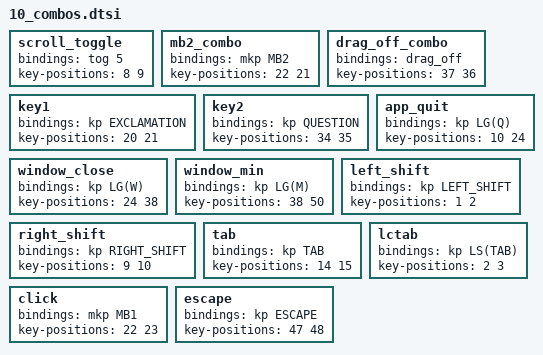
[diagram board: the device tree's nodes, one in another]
/* ============================================================
 * 10_combos.dtsi — コンボ定義
 *
 * combos { compatible = "zmk,combos"; } の内側でインクルードされる。
 * ============================================================ */

scroll_toggle {
    bindings = <&tog 5>;
    key-positions = <8 9>;
};

mb2_combo {
    bindings = <&mkp MB2>;
    key-positions = <22 21>;
};

drag_off_combo {
    bindings = <&drag_off>;
    key-positions = <37 36>;
};

key1 {
    bindings = <&kp EXCLAMATION>;
    key-positions = <20 21>;
};

key2 {
    bindings = <&kp QUESTION>;
    key-positions = <34 35>;
};

app_quit {
    bindings = <&kp LG(Q)>;
    key-positions = <10 24>;
};

window_close {
    bindings = <&kp LG(W)>;
    key-positions = <24 38>;
};

window_min {
    bindings = <&kp LG(M)>;
    key-positions = <38 50>;
};

left_shift {
    bindings = <&kp LEFT_SHIFT>;
    key-positions = <1 2>;
};

right_shift {
    bindings = <&kp RIGHT_SHIFT>;
    key-positions = <9 10>;
};

tab {
    bindings = <&kp TAB>;
    key-positions = <14 15>;
};

lctab {
    bindings = <&kp LS(TAB)>;
    key-positions = <2 3>;
};

click {
    bindings = <&mkp MB1>;
    key-positions = <22 23>;
};

escape {
    bindings = <&kp ESCAPE>;
    key-positions = <47 48>;
};
